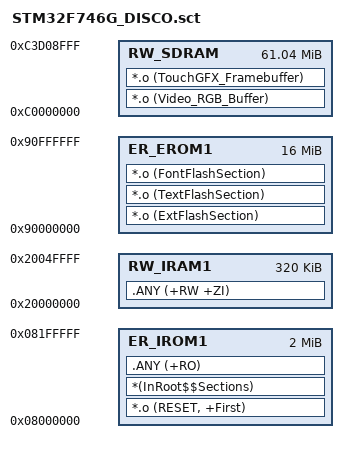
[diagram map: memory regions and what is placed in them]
; *************************************************************
; *** Scatter-Loading Description File generated by uVision ***
; *************************************************************

LR_IROM1 0x08000000 0x00200000  {    ; load region size_region
  ER_IROM1 0x08000000 0x00200000  {  ; load address = execution address
   *.o (RESET, +First)
   *(InRoot$$Sections)
   .ANY (+RO)
  }
  RW_IRAM1 0x20000000 0x00050000  {  ; RW data
   .ANY (+RW +ZI)
  }
  RW_SDRAM 0xC0000000 0x03D09000 {
    *.o (Video_RGB_Buffer)
    *.o (TouchGFX_Framebuffer)
  }
}

LR_EROM1 0x90000000 0x1000000  {    ; load region size_region
  ER_EROM1 0x90000000 0x1000000  {  ; load address = execution address
   *.o (ExtFlashSection)
   *.o (TextFlashSection)
   *.o (FontFlashSection)
  }
}


